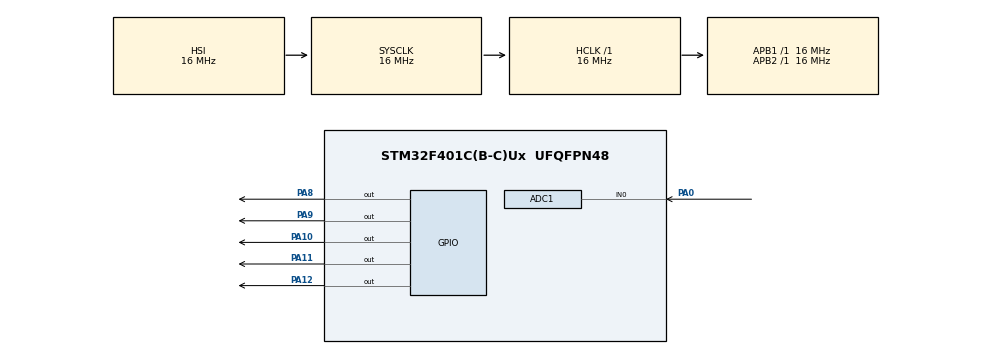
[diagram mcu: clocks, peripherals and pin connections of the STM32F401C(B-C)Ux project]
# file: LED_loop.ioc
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ADC1.Channel-0\#ChannelRegularConversion=ADC_CHANNEL_0
ADC1.NbrOfConversionFlag=1
ADC1.Rank-0\#ChannelRegularConversion=1
ADC1.SamplingTime-0\#ChannelRegularConversion=ADC_SAMPLETIME_3CYCLES
ADC1.master=1
Mcu.Family=STM32F4
Mcu.Name=STM32F401C(B-C)Ux
Mcu.Package=UFQFPN48
NVIC.PriorityGroup=NVIC_PRIORITYGROUP_4
PA0-WKUP.Signal=ADCx_IN0
PA10.Signal=GPIO_Output
PA11.Signal=GPIO_Output
PA12.Signal=GPIO_Output
PA8.Signal=GPIO_Output
PA9.Signal=GPIO_Output
ProjectManager.HeapSize=0x200
ProjectManager.StackSize=0x400
ProjectManager.TargetToolchain=STM32CubeIDE
RCC.AHBFreq_Value=16000000
RCC.APB1Freq_Value=16000000
RCC.APB2Freq_Value=16000000
RCC.CortexFreq_Value=16000000
RCC.HSE_VALUE=25000000
RCC.HSI_VALUE=16000000
RCC.LSE_VALUE=32768
RCC.SYSCLKFreq_VALUE=16000000
RCC.VCOOutputFreq_Value=192000000
SH.ADCx_IN0.0=ADC1_IN0,IN0
board=custom

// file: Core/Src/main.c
/* USER CODE BEGIN Header */
/**
  ******************************************************************************
  * @file           : main.c
  * @brief          : Main program body
  ******************************************************************************
  * @attention
  *
  * Copyright (c) 2022 STMicroelectronics.
  * All rights reserved.
  *
  * This software is licensed under terms that can be found in the LICENSE file
  * in the root directory of this software component.
  * If no LICENSE file comes with this software, it is provided AS-IS.
  *
  ******************************************************************************
  */
/* USER CODE END Header */
#include "main.h"

ADC_HandleTypeDef hadc1;

void SystemClock_Config(void);
static void MX_GPIO_Init(void);
static void MX_ADC1_Init(void);

int main(void)
{

  /* MCU Configuration--------------------------------------------------------*/

  /* Reset of all peripherals, Initializes the Flash interface and the Systick. */
  HAL_Init();

  /* Configure the system clock */
  SystemClock_Config();

  /* Initialize all configured peripherals */
  MX_GPIO_Init();
  MX_ADC1_Init();
  /* USER CODE BEGIN 2 */
  uint16_t pinArr[5] = {GPIO_PIN_8, GPIO_PIN_9, GPIO_PIN_10, GPIO_PIN_11, GPIO_PIN_12};
  uint16_t buffer;
  /* USER CODE END 2 */

  /* Infinite loop */
  /* USER CODE BEGIN WHILE */
  while (1)
  {
	  // 4095 / len(pinArr) * loopsNum = 273
	  HAL_ADC_Start(&hadc1);
	  HAL_GPIO_WritePin(GPIOA, pinArr[buffer = (HAL_ADC_GetValue(&hadc1) / 273) % 5], GPIO_PIN_SET);
	  for(uint8_t i = 0; i < 5; i++)
		if(i != buffer)
		  HAL_GPIO_WritePin(GPIOA, pinArr[i], GPIO_PIN_RESET);
    /* USER CODE END WHILE */

  }
}

void SystemClock_Config(void)
{
  RCC_OscInitTypeDef RCC_OscInitStruct = {0};
  RCC_ClkInitTypeDef RCC_ClkInitStruct = {0};

  /** Configure the main internal regulator output voltage
  */
  __HAL_RCC_PWR_CLK_ENABLE();
  __HAL_PWR_VOLTAGESCALING_CONFIG(PWR_REGULATOR_VOLTAGE_SCALE2);

  /** Initializes the RCC Oscillators according to the specified parameters
  * in the RCC_OscInitTypeDef structure.
  */
  RCC_OscInitStruct.OscillatorType = RCC_OSCILLATORTYPE_HSI;
  RCC_OscInitStruct.HSIState = RCC_HSI_ON;
  RCC_OscInitStruct.HSICalibrationValue = RCC_HSICALIBRATION_DEFAULT;
  RCC_OscInitStruct.PLL.PLLState = RCC_PLL_NONE;
  if (HAL_RCC_OscConfig(&RCC_OscInitStruct) != HAL_OK)
  {
    Error_Handler();
  }

  /** Initializes the CPU, AHB and APB buses clocks
  */
  RCC_ClkInitStruct.ClockType = RCC_CLOCKTYPE_HCLK|RCC_CLOCKTYPE_SYSCLK
                              |RCC_CLOCKTYPE_PCLK1|RCC_CLOCKTYPE_PCLK2;
  RCC_ClkInitStruct.SYSCLKSource = RCC_SYSCLKSOURCE_HSI;
  RCC_ClkInitStruct.AHBCLKDivider = RCC_SYSCLK_DIV1;
  RCC_ClkInitStruct.APB1CLKDivider = RCC_HCLK_DIV1;
  RCC_ClkInitStruct.APB2CLKDivider = RCC_HCLK_DIV1;

  if (HAL_RCC_ClockConfig(&RCC_ClkInitStruct, FLASH_LATENCY_0) != HAL_OK)
  {
    Error_Handler();
  }
}

static void MX_ADC1_Init(void)
{

  ADC_ChannelConfTypeDef sConfig = {0};

  /** Configure the global features of the ADC (Clock, Resolution, Data Alignment and number of conversion)
  */
  hadc1.Instance = ADC1;
  hadc1.Init.ClockPrescaler = ADC_CLOCK_SYNC_PCLK_DIV2;
  hadc1.Init.Resolution = ADC_RESOLUTION_12B;
  hadc1.Init.ScanConvMode = DISABLE;
  hadc1.Init.ContinuousConvMode = DISABLE;
  hadc1.Init.DiscontinuousConvMode = DISABLE;
  hadc1.Init.ExternalTrigConvEdge = ADC_EXTERNALTRIGCONVEDGE_NONE;
  hadc1.Init.ExternalTrigConv = ADC_SOFTWARE_START;
  hadc1.Init.DataAlign = ADC_DATAALIGN_RIGHT;
  hadc1.Init.NbrOfConversion = 1;
  hadc1.Init.DMAContinuousRequests = DISABLE;
  hadc1.Init.EOCSelection = ADC_EOC_SINGLE_CONV;
  if (HAL_ADC_Init(&hadc1) != HAL_OK)
  {
    Error_Handler();
  }

  /** Configure for the selected ADC regular channel its corresponding rank in the sequencer and its sample time.
  */
  sConfig.Channel = ADC_CHANNEL_0;
  sConfig.Rank = 1;
  sConfig.SamplingTime = ADC_SAMPLETIME_3CYCLES;
  if (HAL_ADC_ConfigChannel(&hadc1, &sConfig) != HAL_OK)
  {
    Error_Handler();
  }

}

static void MX_GPIO_Init(void)
{
  GPIO_InitTypeDef GPIO_InitStruct = {0};

  /* GPIO Ports Clock Enable */
  __HAL_RCC_GPIOA_CLK_ENABLE();

  /*Configure GPIO pin Output Level */
  HAL_GPIO_WritePin(GPIOA, GPIO_PIN_8|GPIO_PIN_9|GPIO_PIN_10|GPIO_PIN_11
                          |GPIO_PIN_12, GPIO_PIN_RESET);

  /*Configure GPIO pins : PA8 PA9 PA10 PA11
                           PA12 */
  GPIO_InitStruct.Pin = GPIO_PIN_8|GPIO_PIN_9|GPIO_PIN_10|GPIO_PIN_11
                          |GPIO_PIN_12;
  GPIO_InitStruct.Mode = GPIO_MODE_OUTPUT_PP;
  GPIO_InitStruct.Pull = GPIO_NOPULL;
  GPIO_InitStruct.Speed = GPIO_SPEED_FREQ_LOW;
  HAL_GPIO_Init(GPIOA, &GPIO_InitStruct);

}

void Error_Handler(void)
{
  __disable_irq();
  while (1)
  {
  }
}
